# iqn_at register map
Vendor: Texas Instruments
Peripheral module from a debugger description file (folder Keystone2).
Registers are 32-bit, read-only, no defined reset value unless marked. A register's access mark holds for its fields unless they carry their own. Offsets are as the file gives them; lines under a group give offsets from that group; [hi:lo] are bit positions; {n}, {i} and the like mark numbered series; 'fields as' and 'values as' point back to an identical list; <NAME> marks a mode.

## IQN_AT
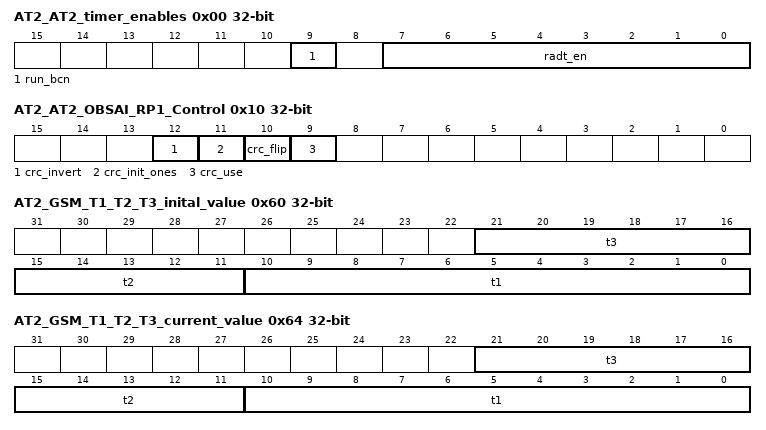
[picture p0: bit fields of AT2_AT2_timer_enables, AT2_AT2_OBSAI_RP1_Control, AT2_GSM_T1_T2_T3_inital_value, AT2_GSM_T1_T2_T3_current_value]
0x00 AT2_AT2_timer_enables rw — (1 of 1, stride 0)
  [9] run_bcn — SW control which starts the BCN Timer running. SW writes are not precise so it is expected the user will correct the timer value with an offset.
  [7:0] radt_en — bit 0-7 enable RadT0-to-RadT7. RADT 7 will be used for driving the t1-t2-t3 GSM Timer. Once enabled, Timers will start running once the compare value equals the BCN timer value (which yeilds an exact sync)
0x10 AT2_AT2_OBSAI_RP1_Control rw — (1 of 1, stride 0)
  [12] crc_invert — Enables bit-by-bit inversion of calculated CRC value prior to comparison.
  [11] crc_init_ones — Initialization value of the CRC engine.
  [10] crc_flip — CRC bit order select.
  [9] crc_use — When set to a 1, a failed CRC check will result in the FCB being dropped.
0x14 AT2_AT2_rp1_type_capture — (1 of 1, stride 0)
  [7:0] rd_val — RP1 Type field captured
0x18 AT2_RP1_TOD_Capture_LSBs — (1 of 1, stride 0)
  [31:0] rd_val — RP1 payload capture 32 LSBs
0x1C AT2_RP1_TOD_Capture_MSBs — (1 of 1, stride 0)
  [31:0] rd_val — RP1 payload capture 32 MSBs
0x20 AT2_AT2_BCN_offset rw — (1 of 1, stride 0)
  [24:0] val — Offset for the free running raw BCN counter. The offset version of BCN is the value used for all measurement and sync purposes. (The offset mechanism gives a way to minimize clock domains crossing errors when syncing timers).SW uses the desired sync input
0x24 AT2_BCN_pa_tscomp_capture — (1 of 1, stride 0)
  [24:0] rd_val — BCN clock count pa_tscomp capture
0x28 AT2_BCN_physync_capture — (1 of 1, stride 0)
  [24:0] rd_val — BCN clock count physync capture
0x2C AT2_BCN_radsync_capture — (1 of 1, stride 0)
  [24:0] rd_val — BCN clock count radsync capture
0x30 AT2_BCN_rp1_sync_capture — (1 of 1, stride 0)
  [24:0] rd_val — BCN clock count rp1_sync capture
0x34 AT2_BCN_uAT_slave_sync_capture — (1 of 1, stride 0)
  [24:0] rd_val — BCN clock count selected slave uAT sync capture. bcn_slvsel_cfg selects which uAT slave sync is used for capturing the BCN value in this register.
0x38 AT2_BCN_Frame_Value_LSBs — (1 of 1, stride 0)
  [11:0] rd_val — BCN Frame Value LSBs
0x3C AT2_BCN_Frame_Value_MSBs — (1 of 1, stride 0)
  [27:0] rd_val — BCN Frame Value MSBs
0x40 AT2_BCN_uat_slave_select rw — (1 of 1, stride 0)
  [3:0] val — BCN uat slave select for choosing which of up to 16 uats is used as the source of the sync signal.
0x44 AT2_BCN_Frame_Init_LSBs wo — (1 of 1, stride 0)
  [11:0] wr_val — BCN Frame Init LSBs
0x48 AT2_BCN_Frame_Init_MSBs wo — (1 of 1, stride 0)
  [27:0] wr_val — BCN Frame Init MSBs
0x4C AT2_BCN_Clock_Counter_TC rw — (1 of 1, stride 0)
  [24:0] val — BCN Clock Counter TC. Set to one less than the number of clock cycles needed.
0x50 AT2_BCN_Frame_TC_LSBs rw — (1 of 1, stride 0)
  [31:0] val — BCN Frame TC LSBs
0x54 AT2_BCN_Frame_TC_MSBs rw — (1 of 1, stride 0)
  [7:0] val — BCN Frame TC MSBs. Frame count goes to 0 when it matches the concatenated MSB and LSB value of these two registers.
0x60 AT2_GSM_T1_T2_T3_inital_value wo — (1 of 1, stride 0)
  [21:16] t3 — T3 w=init, affects at_gsm_tcount_value
  [15:11] t2 — T2 w=init, affects at_gsm_tcount_value
  [10:0] t1 — T1 w=init, affects at_gsm_tcount_value
0x64 AT2_GSM_T1_T2_T3_current_value — (1 of 1, stride 0)
  [21:16] t3 — T3 r=value of T3 counter
  [15:11] t2 — T2 r=value of T2 counter
  [10:0] t1 — T1 r=value of T1 counter
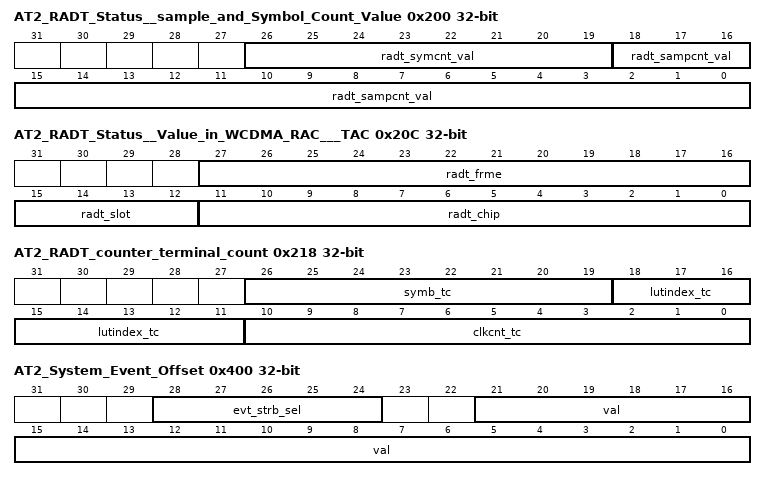
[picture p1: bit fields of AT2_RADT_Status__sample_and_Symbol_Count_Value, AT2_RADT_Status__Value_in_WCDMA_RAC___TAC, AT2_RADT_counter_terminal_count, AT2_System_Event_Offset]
0x200 AT2_RADT_Status__sample_and_Symbol_Count_Value — (1 of 8, stride 64)
  [26:19] radt_symcnt_val — RADT symbol count Value
  [18:0] radt_sampcnt_val — RADT sample count Value. Increments every radt_0_cfg clkcnt_tc +1 system clock cycles.
0x204 AT2_RADT_Status__Frame_Count_Value_LSBs — (1 of 8, stride 64)
  [11:0] radt_frm_val_lsb — RADT Frame Value 12 LSBs
0x208 AT2_RADT_Status__Frame_Value_MSBs — (1 of 8, stride 64)
  [27:0] radt_frm_val_msb — RADT Frame Value MSBs
0x20C AT2_RADT_Status__Value_in_WCDMA_RAC___TAC — (1 of 8, stride 64)
  [27:16] radt_frme — Frame Value
  [15:12] radt_slot — Slot Value
  [11:0] radt_chip — Chip Value
0x210 AT2_RADT_Frame_Init_LSBs wo — (1 of 8, stride 64)
  [11:0] frm_init_lsb — RADT Frame Init LSBs loads a frame count directly to the counter LSB bits. This register and the MSB register should only be loaded when the RADT is off or if it is known it will not be incrementing during the time of the writes.
0x214 AT2_RADT_Frame_Init_MSBs wo — (1 of 8, stride 64)
  [27:0] frm_init_msb — RADT Frame Init MSBs loads a frame count directly to the counter MSB bits. This register and the LSB register should only be loaded when the RADT is off or if it is known it will not be incrementing during the time of the writes.
0x218 AT2_RADT_counter_terminal_count rw — (1 of 8, stride 64)
  [26:19] symb_tc — Symbol TC 8bit. This is the number of symbols in the frame minus 1.
  [18:11] lutindex_tc — LUT Index TC 8bit. This is the number of sample entries in the table minus 1 plus the offset into the LUT for the start of the table for this RADT. It is typically either a 0 when all symbols are the same size or it is the number of symbols in the frame
  [10:0] clkcnt_tc — Clock divider counter TC 11bit. The clock divider divides down the clock to a sample period before driving the sample counter. represents num clock ticks minus 1 per sample
0x220 AT2_RADT_Frame_TC_LSBs rw — (1 of 8, stride 64)
  [31:0] frm_tc_lsb — RADT Frame TC LSBs
0x224 AT2_RADT_Frame_TC_MSBs rw — (1 of 8, stride 64)
  [7:0] frm_tc_msb — RADT Frame TC MSBs
0x228 AT2_RADT_Base_Address_for_INDEX rw — (1 of 8, stride 64)
  [7:0] lut_index_strt — LUT Index start address pointer to the symbol lut memory for this RADT.
0x22C AT2_BCN_sync_compare_value rw — (1 of 8, stride 64)
  [24:0] bcn_sync_cmp — BCN compare value for synchronization to start the RADT. The RADT starts on the next occurance of the BCN counter matching this value after being enabled and is ignored after that as long as the RADT is enabled.
0x400 AT2_System_Event_Offset rw — (1 of 24, stride 16)
  [28:24] evt_strb_sel — Selects which RADT counter and start-of-symbol vs. start-of-frame. (Step 1) Each the selected strobe fires, the given sys_event generator resets
  [21:0] val — Event Offset Index. This is the number of system clocks after the selected RADT event that the event is triggerred.
0x404 AT2_System_Event_Modulo_Terminal_Count rw — (1 of 24, stride 16)
  [21:0] val — Event Modulo. Minimum programmed value should be 15. This corresponds to a minimum modulo of 16.
0x408 AT2_System_Event_Mask__LSBs rw — (1 of 24, stride 16)
  [31:0] val — Event Mask LSBs. all 0 will disable events, A 1 in a bit enables that event time. Typically set these to all ones when GSM masking is not desired.
0x40C AT2_System_Event_Mask__MSBs rw — (1 of 24, stride 16)
  [31:0] val — Event Mask MSBs. all 0 will disable events, A 1 in a bit enables that event time. Typically set these to all ones when GSM masking is not desired.
0x600 AT2_System_Event_Enables rw — (1 of 1, stride 0)
  [23:0] en — EVENT Enable when a bit is set to a 1. Must be enabled after event configuration.
0x604 AT2_System_Event_Force_Register wo — (1 of 1, stride 0)
  [23:0] strb — EVENT Force causes an event when set to a 1 on the corresponding system event.
0x800 AT2_AT2_symbol_lut_RAM rw — (1 of 256, stride 4)
  [18:0] symbcnt_tc — RadT symbol counter terminal count programmed in sys_clks (usually 245.76MHz or 307.2MHz) Set to the number of clock cycles needed minus 1. If all symbols are the same size only 1 location needs to be used, otherwise a separate location is needed for each
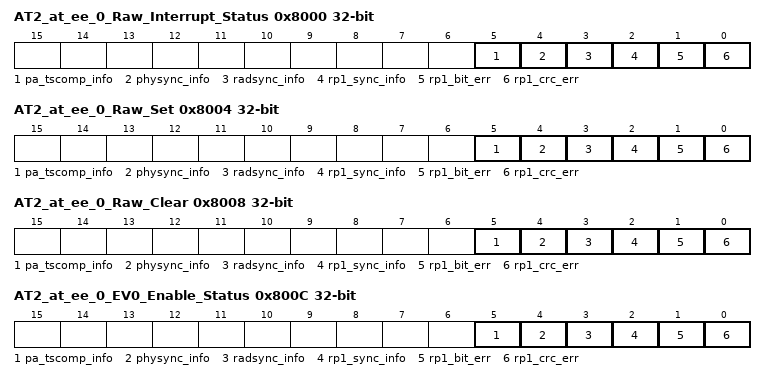
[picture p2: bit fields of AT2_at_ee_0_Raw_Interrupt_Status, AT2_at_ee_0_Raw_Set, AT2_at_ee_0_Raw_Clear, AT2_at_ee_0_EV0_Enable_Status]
0x8000 AT2_at_ee_0_Raw_Interrupt_Status — (1 of 1, stride 0)
  [5] pa_tscomp_info — A pa_tscomp sync input was received from NETCP PA (Valid when using IEEE1588 sync). BCN value was captured for use by APP SW to calc and correct BCN alignment
  [4] physync_info — A strobe was recieved on the phyt (BCN) sync input pin (Only valid when using external sync pin) BCN value was captured for use by APP SW to calc and correct BCN alignment
  [3] radsync_info — A strobe was recieved on the radt sync input pin (Only valid when using external sync pin). BCN value was captured for use by APP SW to calc and correct RADT alignment
  [2] rp1_sync_info — An RP1 FCB packet was received (Only valid with using OBSAI RP1 Sync Interface). BCN value was captured for use by APP SW to calc and correct BCN alignment
  [1] rp1_bit_err — RP1 bit error (Only valid with using OBSAI RP1 Sync Interface). RP1 FCB recieved pattern is illegal. Data bits were not held for 8 consecutive RP1_clks
  [0] rp1_crc_err — RP1 CRC error (Only valid with using OBSAI RP1 Sync Interface). RP1 FCB was recieved with bad CRC. APP SW should disregard FCB
0x8004 AT2_at_ee_0_Raw_Set wo — (1 of 1, stride 0)
  [5] pa_tscomp_info — Sets the corresponding bit in the raw_status register when set. Write only, self-clears.
  [4] physync_info — Sets the corresponding bit in the raw_status register when set. Write only, self-clears.
  [3] radsync_info — Sets the corresponding bit in the raw_status register when set. Write only, self-clears.
  [2] rp1_sync_info — Sets the corresponding bit in the raw_status register when set. Write only, self-clears.
  [1] rp1_bit_err — Sets the corresponding bit in the raw_status register when set. Write only, self-clears.
  [0] rp1_crc_err — Sets the corresponding bit in the raw_status register when set. Write only, self-clears.
0x8008 AT2_at_ee_0_Raw_Clear wo — (1 of 1, stride 0)
  [5] pa_tscomp_info — Clears the corresponding bit in the raw_status register when set. Write only, self-clears.
  [4] physync_info — Clears the corresponding bit in the raw_status register when set. Write only, self-clears.
  [3] radsync_info — Clears the corresponding bit in the raw_status register when set. Write only, self-clears.
  [2] rp1_sync_info — Clears the corresponding bit in the raw_status register when set. Write only, self-clears.
  [1] rp1_bit_err — Clears the corresponding bit in the raw_status register when set. Write only, self-clears.
  [0] rp1_crc_err — Clears the corresponding bit in the raw_status register when set. Write only, self-clears.
0x800C AT2_at_ee_0_EV0_Enable_Status — (1 of 1, stride 0)
  [5] pa_tscomp_info — When set allows the corresponding bit in the raw_status register to generate the intr_sts interrupt. Read only.
  [4] physync_info — When set allows the corresponding bit in the raw_status register to generate the intr_sts interrupt. Read only.
  [3] radsync_info — When set allows the corresponding bit in the raw_status register to generate the intr_sts interrupt. Read only.
  [2] rp1_sync_info — When set allows the corresponding bit in the raw_status register to generate the intr_sts interrupt. Read only.
  [1] rp1_bit_err — When set allows the corresponding bit in the raw_status register to generate the intr_sts interrupt. Read only.
  [0] rp1_crc_err — When set allows the corresponding bit in the raw_status register to generate the intr_sts interrupt. Read only.
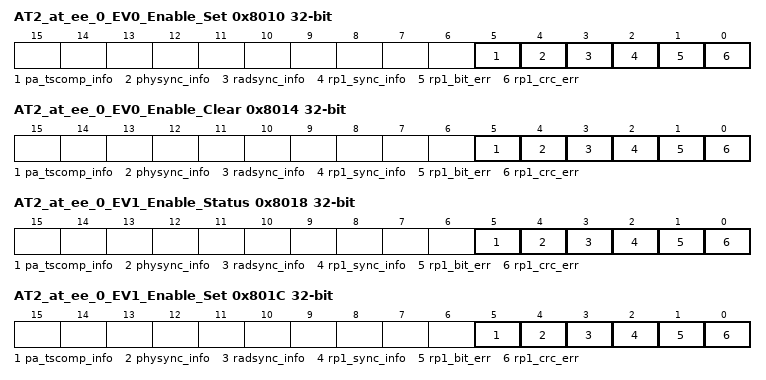
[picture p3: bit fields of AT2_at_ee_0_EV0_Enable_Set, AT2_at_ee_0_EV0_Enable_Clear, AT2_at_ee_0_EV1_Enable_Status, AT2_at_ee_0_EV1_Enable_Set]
0x8010 AT2_at_ee_0_EV0_Enable_Set wo — (1 of 1, stride 0)
  [5] pa_tscomp_info — Sets the corresponding bit in the enable register when set. Write only, self-clears.
  [4] physync_info — Sets the corresponding bit in the enable register when set. Write only, self-clears.
  [3] radsync_info — Sets the corresponding bit in the enable register when set. Write only, self-clears.
  [2] rp1_sync_info — Sets the corresponding bit in the enable register when set. Write only, self-clears.
  [1] rp1_bit_err — Sets the corresponding bit in the enable register when set. Write only, self-clears.
  [0] rp1_crc_err — Sets the corresponding bit in the enable register when set. Write only, self-clears.
0x8014 AT2_at_ee_0_EV0_Enable_Clear wo — (1 of 1, stride 0)
  [5] pa_tscomp_info — Clears the corresponding bit in the enable register when set. Write only, self-clears.
  [4] physync_info — Clears the corresponding bit in the enable register when set. Write only, self-clears.
  [3] radsync_info — Clears the corresponding bit in the enable register when set. Write only, self-clears.
  [2] rp1_sync_info — Clears the corresponding bit in the enable register when set. Write only, self-clears.
  [1] rp1_bit_err — Clears the corresponding bit in the enable register when set. Write only, self-clears.
  [0] rp1_crc_err — Clears the corresponding bit in the enable register when set. Write only, self-clears.
0x8018 AT2_at_ee_0_EV1_Enable_Status — (1 of 1, stride 0)
  [5] pa_tscomp_info — When set allows the corresponding bit in the raw_status register to generate the intr1_sts interrupt. Read only.
  [4] physync_info — When set allows the corresponding bit in the raw_status register to generate the intr1_sts interrupt. Read only.
  [3] radsync_info — When set allows the corresponding bit in the raw_status register to generate the intr1_sts interrupt. Read only.
  [2] rp1_sync_info — When set allows the corresponding bit in the raw_status register to generate the intr1_sts interrupt. Read only.
  [1] rp1_bit_err — When set allows the corresponding bit in the raw_status register to generate the intr1_sts interrupt. Read only.
  [0] rp1_crc_err — When set allows the corresponding bit in the raw_status register to generate the intr1_sts interrupt. Read only.
0x801C AT2_at_ee_0_EV1_Enable_Set wo — (1 of 1, stride 0)
  [5] pa_tscomp_info — Sets the corresponding bit in the intr1_status register when set. Write only, self-clears.
  [4] physync_info — Sets the corresponding bit in the intr1_status register when set. Write only, self-clears.
  [3] radsync_info — Sets the corresponding bit in the intr1_status register when set. Write only, self-clears.
  [2] rp1_sync_info — Sets the corresponding bit in the intr1_status register when set. Write only, self-clears.
  [1] rp1_bit_err — Sets the corresponding bit in the intr1_status register when set. Write only, self-clears.
  [0] rp1_crc_err — Sets the corresponding bit in the intr1_status register when set. Write only, self-clears.
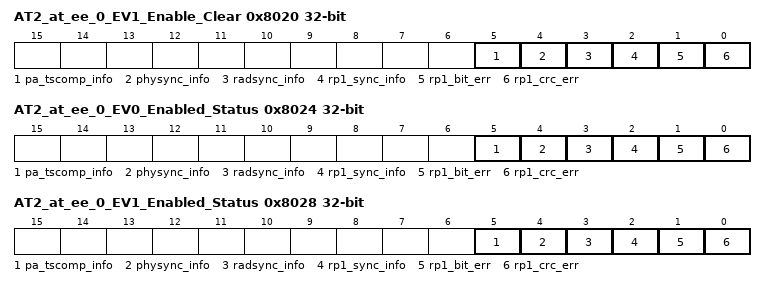
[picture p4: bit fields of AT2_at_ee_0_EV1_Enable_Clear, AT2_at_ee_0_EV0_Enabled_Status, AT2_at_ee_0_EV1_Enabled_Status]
0x8020 AT2_at_ee_0_EV1_Enable_Clear wo — (1 of 1, stride 0)
  [5] pa_tscomp_info — Clears the corresponding bit in the intr1_status register when set. Write only, self-clears.
  [4] physync_info — Clears the corresponding bit in the intr1_status register when set. Write only, self-clears.
  [3] radsync_info — Clears the corresponding bit in the intr1_status register when set. Write only, self-clears.
  [2] rp1_sync_info — Clears the corresponding bit in the intr1_status register when set. Write only, self-clears.
  [1] rp1_bit_err — Clears the corresponding bit in the intr1_status register when set. Write only, self-clears.
  [0] rp1_crc_err — Clears the corresponding bit in the intr1_status register when set. Write only, self-clears.
0x8024 AT2_at_ee_0_EV0_Enabled_Status — (1 of 1, stride 0)
  [5] pa_tscomp_info — AND-ed raw_status bits with the corresponding bit in the enable_status register. Read only.
  [4] physync_info — AND-ed raw_status bits with the corresponding bit in the enable_status register. Read only.
  [3] radsync_info — AND-ed raw_status bits with the corresponding bit in the enable_status register. Read only.
  [2] rp1_sync_info — AND-ed raw_status bits with the corresponding bit in the enable_status register. Read only.
  [1] rp1_bit_err — AND-ed raw_status bits with the corresponding bit in the enable_status register. Read only.
  [0] rp1_crc_err — AND-ed raw_status bits with the corresponding bit in the enable_status register. Read only.
0x8028 AT2_at_ee_0_EV1_Enabled_Status — (1 of 1, stride 0)
  [5] pa_tscomp_info — AND-ed raw_status bits with the corresponding bit in the intr1_status register. Read only.
  [4] physync_info — AND-ed raw_status bits with the corresponding bit in the intr1_status register. Read only.
  [3] radsync_info — AND-ed raw_status bits with the corresponding bit in the intr1_status register. Read only.
  [2] rp1_sync_info — AND-ed raw_status bits with the corresponding bit in the intr1_status register. Read only.
  [1] rp1_bit_err — AND-ed raw_status bits with the corresponding bit in the intr1_status register. Read only.
  [0] rp1_crc_err — AND-ed raw_status bits with the corresponding bit in the intr1_status register. Read only.
